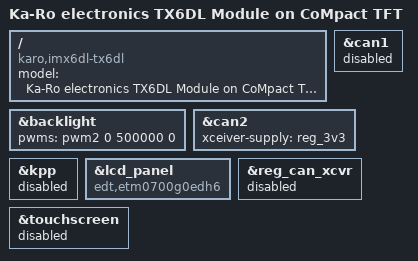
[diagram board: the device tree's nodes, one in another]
/dts-v1/;
#include "imx6dl.dtsi"
#include "imx6qdl-tx6.dtsi"
#include "imx6qdl-tx6-lcd.dtsi"
/ {
	model = "Ka-Ro electronics TX6DL Module on CoMpact TFT";
	compatible = "karo,imx6dl-tx6dl", "fsl,imx6dl";
};
&backlight {
	pwms = <&pwm2 0 500000 0>;
	/delete-property/ turn-on-delay-ms;
};
&can1 {
	status = "disabled";
};
&can2 {
	xceiver-supply = <&reg_3v3>;
};
&kpp {
	status = "disabled";
};
&lcd_panel {
	compatible = "edt,etm0700g0edh6";
};
&reg_can_xcvr {
	status = "disabled";
};
&touchscreen {
	status = "disabled";
};
